# ATmega325PA device description
Architecture: AVR8; Family: megaAVR
Registers are 8-bit, access not given, no defined reset value unless marked. A register's access mark holds for its fields unless they carry their own. Offsets are from the block's base; [hi:lo] are bit positions.

## TC1 (TC16 module) — Timer/Counter, 16-bit
Instances: TC1 0x00
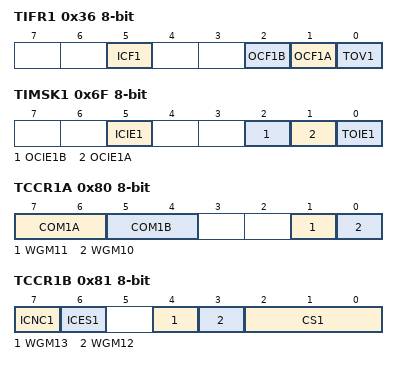
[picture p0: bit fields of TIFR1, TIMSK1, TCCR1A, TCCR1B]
0x36 TIFR1 — Timer/Counter1 Interrupt Flag register
  [5] ICF1 — Input Capture Flag 1
  [2] OCF1B — Output Compare Flag 1B
  [1] OCF1A — Output Compare Flag 1A
  [0] TOV1 — Timer/Counter1 Overflow Flag
0x6F TIMSK1 — Timer/Counter1 Interrupt Mask Register
  [5] ICIE1 — Timer/Counter1 Input Capture Interrupt Enable
  [2] OCIE1B — Timer/Counter1 Output Compare B Match Interrupt Enable
  [1] OCIE1A — Timer/Counter1 Output Compare A Match Interrupt Enable
  [0] TOIE1 — Timer/Counter1 Overflow Interrupt Enable
0x80 TCCR1A — Timer/Counter1 Control Register A
  [7:6] COM1A — Compare Output Mode 1A, bits
  [5:4] COM1B — Compare Output Mode 1B, bits
  [1] WGM11 — Waveform Generation Mode
  [0] WGM10 — Waveform Generation Mode
0x81 TCCR1B — Timer/Counter1 Control Register B
  [7] ICNC1 — Input Capture 1 Noise Canceler
  [6] ICES1 — Input Capture 1 Edge Select
  [4] WGM13 (bit 2 of the value upward) — Waveform Generation Mode
  [3] WGM12 (bit 2 of the value upward) — Waveform Generation Mode
  [2:0] CS1 — Prescaler source of Timer/Counter 1
    0=No Clock Source (Stopped); 1=Running, No Prescaling; 2=Running, CLK/8; 3=Running, CLK/64; 4=Running, CLK/256; 5=Running, CLK/1024; 6=Running, ExtClk Tx Falling Edge; 7=Running, ExtClk Tx Rising Edge
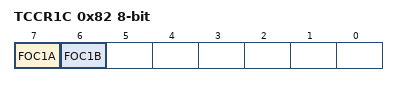
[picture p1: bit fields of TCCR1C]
0x82 TCCR1C — Timer/Counter 1 Control Register C
  [7] FOC1A — Force Output Compare 1A
  [6] FOC1B — Force Output Compare 1B
0x84 TCNT1 16-bit — Timer/Counter1 Bytes
0x86 ICR1 16-bit — Timer/Counter1 Input Capture Register Bytes
0x88 OCR1A 16-bit — Timer/Counter1 Output Compare Register A Bytes
0x8A OCR1B 16-bit — Timer/Counter1 Output Compare Register B Bytes

## TC2 (TC8_ASYNC module) — Timer/Counter, 8-bit Async
Instances: TC2 0x00
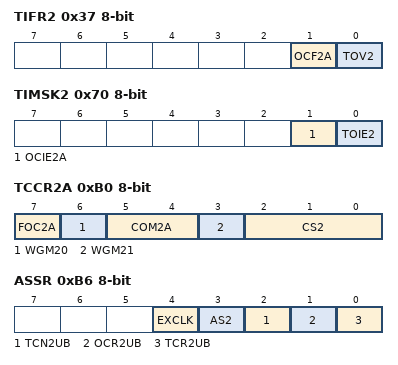
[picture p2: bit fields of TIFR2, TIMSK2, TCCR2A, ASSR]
0x37 TIFR2 — Timer/Counter2 Interrupt Flag Register
  [1] OCF2A — Timer/Counter2 Output Compare Flag 2
  [0] TOV2 — Timer/Counter2 Overflow Flag
0x43 GTCCR — General Timer/Counter Control Register
  [1] PSR2 — Prescaler Reset Timer/Counter2
0x70 TIMSK2 — Timer/Counter2 Interrupt Mask register
  [1] OCIE2A — Timer/Counter2 Output Compare Match Interrupt Enable
  [0] TOIE2 — Timer/Counter2 Overflow Interrupt Enable
0xB0 TCCR2A — Timer/Counter2 Control Register
  [7] FOC2A — Force Output Compare A
  [6] WGM20 — Waveform Generation Mode
    0=Normal; 2=PWM, Phase Correct; 1=CTC; 3=Fast PWM
  [5:4] COM2A — Compare Output Mode bits
  [3] WGM21 — Waveform Generation Mode
  [2:0] CS2 — Clock Select bits
    0=No Clock Source (Stopped); 1=Running, No Prescaling; 2=Running, CLK/8; 3=Running, CLK/32; 4=Running, CLK/64; 5=Running, CLK/128; 6=Running, CLK/256; 7=Running, CLK/1024
0xB2 TCNT2 — Timer/Counter2
0xB3 OCR2A — Timer/Counter2 Output Compare Register
0xB6 ASSR — Asynchronous Status Register
  [4] EXCLK — Enable External Clock Interrupt
  [3] AS2 — AS2: Asynchronous Timer/Counter2
  [2] TCN2UB — TCN2UB: Timer/Counter2 Update Busy
  [1] OCR2UB — Output Compare Register2 Update Busy
  [0] TCR2UB — TCR2UB: Timer/Counter Control Register2 Update Busy

## WDT — Watchdog Timer
Instances: WDT 0x00
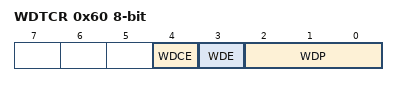
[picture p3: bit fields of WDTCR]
0x60 WDTCR — Watchdog Timer Control Register
  [4] WDCE — Watchdog Change Enable
  [3] WDE — Watch Dog Enable
  [2:0] WDP — Watch Dog Timer Prescaler bits
    0=Oscillator Cycles 16K; 1=Oscillator Cycles 32K; 2=Oscillator Cycles 64K; 3=Oscillator Cycles 128K; 4=Oscillator Cycles 256K; 5=Oscillator Cycles 512K; 6=Oscillator Cycles 1024K; 7=Oscillator Cycles 2048K

## CPU — CPU Registers
Instances: CPU 0x00
Parameters: CORE_VERSION=V2E
0x3E GPIOR0 — General Purpose IO Register 0
0x4A GPIOR1 — General Purpose IO Register 1
0x4B GPIOR2 — General Purpose IO Register 2
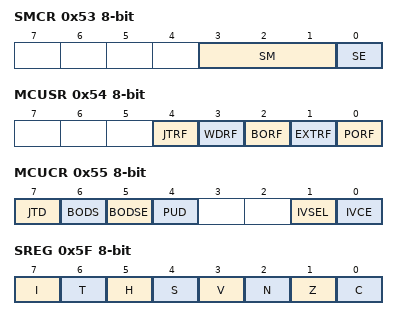
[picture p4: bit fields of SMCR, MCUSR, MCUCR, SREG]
0x53 SMCR — Sleep Mode Control Register
  [3:1] SM — Sleep Mode Select bits
    0=IDLE; 1=ADC (ADC Noise Reduction (If Available)); 2=PDOWN (Power Down); 3=PSAVE (Power Save); 6=STDBY (Standby)
  [0] SE — Sleep Enable
0x54 MCUSR — MCU Status Register
  [4] JTRF — JTAG Reset Flag
  [3] WDRF — Watchdog Reset Flag
  [2] BORF — Brown-out Reset Flag
  [1] EXTRF — External Reset Flag
  [0] PORF — Power-on reset flag
0x55 MCUCR — MCU Control Register
  [7] JTD — JTAG Interface Disable
  [6] BODS — BOD Sleep
  [5] BODSE — BOD Sleep Enable
  [4] PUD — Pull-up disable
  [1] IVSEL — Interrupt Vector Select
  [0] IVCE — Interrupt Vector Change Enable
0x5D SP 16-bit — Stack Pointer
0x5F SREG — Status Register
  [7] I — Global Interrupt Enable
  [6] T — Bit Copy Storage
  [5] H — Half Carry Flag
  [4] S — Sign Bit
  [3] V — Two's Complement Overflow Flag
  [2] N — Negative Flag
  [1] Z — Zero Flag
  [0] C — Carry Flag
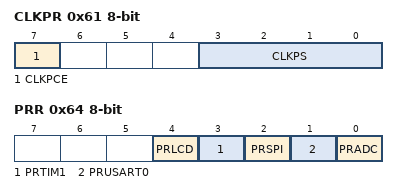
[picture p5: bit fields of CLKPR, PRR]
0x61 CLKPR — Clock Prescale Register
  [7] CLKPCE — Clock Prescaler Change Enable
  [3:0] CLKPS — Clock Prescaler Select Bits
    0=1; 1=2; 2=4; 3=8; 4=16; 5=32; 6=64; 7=128; 8=256
0x64 PRR — Power Reduction Register
  [4] PRLCD — Power Reduction LCD
  [3] PRTIM1 — Power Reduction Timer/Counter1
  [2] PRSPI — Power Reduction Serial Peripheral Interface
  [1] PRUSART0 — Power Reduction USART
  [0] PRADC — Power Reduction ADC
0x66 OSCCAL — Oscillator Calibration Value
  [7:0] OSCCAL — Oscillator Calibration
Value list OSCCAL_VALUE_ADDRESSES: 0=8_0_MHz
